# ICSSM_ICSSM_PR1_ICSSS_UART_UART_SLV_48028000h register map
Vendor: Texas Instruments
Peripheral module from a debugger description file (folder AM263X).
Registers are 32-bit, read-write, reset 0x0 unless marked. A register's access mark holds for its fields unless they carry their own. Offsets are as the file gives them; lines under a group give offsets from that group; [hi:lo] are bit positions; {n}, {i} and the like mark numbered series; 'fields as' and 'values as' point back to an identical list; <NAME> marks a mode.

## ICSSM_PR1_ICSSS_UART_UART_SLV
0x00 ICSSM_PR1_ICSSS_UART_UART_SLV_RBR ro — Receiver Buffer Register (read only)The UART receiver section consists of a receiver shift register (RSR) and a receiver buffer register (RBR). When the UART is in the FIFO mode, RBR is a 16-byte FIFO. Timing is supplied by the 16x receiver clock or 13x receiver clock by programming OSM_SEL bit field of MDR register. Receiver section control is a function of the line control register (LCR).RSR receives serial data from the UARTn_RXD pin. Then RSR concatenates the data and moves it into RBR (or the receiver FIFO). In the non-FIFO mode, when a character is placed in RBR and the receiver data-ready interrupt is enabled (DR = 1 in IER), an interrupt is generated. This interrupt is cleared when the character is read from RBR. In the FIFO mode, the interrupt is generated when the FIFO is filled to the trigger level selected in the FIFO control register (FCR), and it is cleared when the FIFO contents drop below the trigger level.
  [7:0] DATA — Received Data
0x00 ICSSM_PR1_ICSSS_UART_UART_SLV_THR wo — The transmitter holding register (THR) (write only)The UART transmitter section consists of a transmitter hold register (THR) and a transmitter shift register (TSR). When the UART is in the FIFO mode, THR is a 16-byte FIFO. Transmitter section control is a function of the line control register (LCR).THR receives data from the internal data bus and when TSR is idle, the UART moves the data from THR to TSR. The UART serializes the data in TSR and transmits the data on the TX pin. In the non-FIFO mode, if THR is empty and the THR empty (THRE) interrupt is enabled (ETBEI = 1 in IER), an interrupt is generated. This interrupt is cleared when a character is loaded into THR or the interrupt identification register (IIR) is read. In the FIFO mode, the interrupt is generated when the transmitter FIFO is empty, and it is cleared when at least one byte is loaded into the FIFO or IIR is read.
  [7:0] DATA — Data to transmit
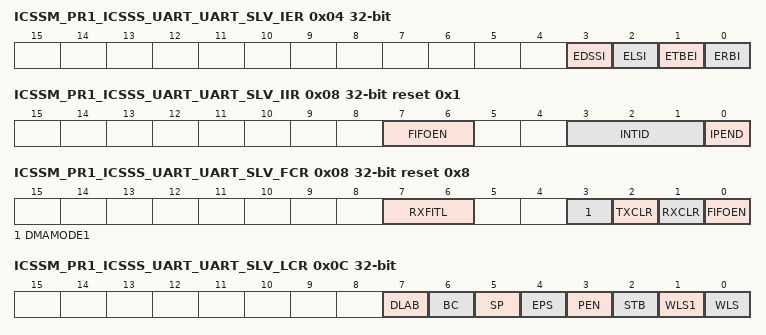
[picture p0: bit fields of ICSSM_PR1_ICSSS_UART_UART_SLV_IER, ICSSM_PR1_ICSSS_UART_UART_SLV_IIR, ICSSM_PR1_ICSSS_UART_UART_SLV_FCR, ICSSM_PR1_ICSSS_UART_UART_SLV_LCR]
0x04 ICSSM_PR1_ICSSS_UART_UART_SLV_IER — The interrupt enable register (IER) is used to individually enable or disable each type of interrupt request that can be generated by the UART. Each interrupt request that is enabled in IER is forwarded to the CPU.
  [3] EDSSI — Enable for Modem Status Interrupt
  [2] ELSI — Enable for Receiver Line Status Interrupt 0h Receiver line status interrupt is disabled.1h Received line status is enabled
  [1] ETBEI — Enable for Transmitter Holding Register Empty Interrupt 0h Transmitter holding register empty interrupt is disabled.1h Transmitter holding register empty interrupt is enabled.
  [0] ERBI — Enable for Receiver Data Available Interrupt 0h Receiver data available interrupt and character timeout indication interrupt is disabled.1h Receiver data available interrupt and character timeout indication interrupt is enabled.
0x08 ICSSM_PR1_ICSSS_UART_UART_SLV_IIR ro reset 0x1 — The interrupt identification register (IIR) is a read-only register at the same address as the FIFO control register (FCR), which is a write-only register. When an interrupt is generated and enabled in the interrupt enable register (IER), IIR indicates that an interrupt is pending in the IPEND bit and encodes the type of interrupt in the INTID bits. Reading IIR clears any THR empty (THRE) interrupts that are pending.
  [7:6] FIFOEN — FIFOs enabled 0h Non-FIFO mode1h-2h Reserved3h FIFOs are enabled. FIFOEN bit in the FIFO control register (FCR) is set to 1.
  [3:1] INTID — Interrupt Type 0h Reserved1h Transmitter holding register empty (priority 3)2h Receiver data available (priority 2)3h Receiver line status (priority 1, highest)4h-5h Reserved6h Character timeout indication (priority 2)7h Reserved
  [0] IPEND — Interrupt pending.When any UART interrupt is generated and is enabled in IER, IPEND is forced to 0. IPEND remains 0 until all pending interrupts are cleared or until a hardware reset occurs. If no interrupts are enabled, IPEND is never forced to 0. 0h Interrupts pending1h No interrupts pending
0x08 ICSSM_PR1_ICSSS_UART_UART_SLV_FCR wo reset 0x8 — FIFO Control Register (write only)The FIFO control register (FCR) is a write-only register at the same address as the interrupt identification register (IIR), which is a read-only register.
  [7:6] RXFITL — Receiver FIFO trigger level.RXFIFTL sets the trigger level for the receiver FIFO.When the trigger level is reached, a receiver data-ready interrupt is generated (if the interrupt request is enabled).Once the FIFO drops below the trigger level, the interrupt is cleared. 0h 1 byte1h 4 bytes2h 8 bytes3h 14 bytes
  [3] DMAMODE1 — DMA MODE1 enable if FIFOs are enabled.Always write 1 to DMAMODE1.After a hardware reset, change DMAMODE1 from 0 to 1.DMAMODE1 = 1 is a requirement for proper communication between the UART and the EDMA controller. 0h DMA MODE 1 is disabled1h DMA MODE 1 is enabled
  [2] TXCLR — Transmitter FIFO clear. Write a 1 to TXCLR to clear the bit. 0h No effect1h Clears transmitter FIFO and resets the transmitter FIFO counter. The shift register is not cleared.
  [1] RXCLR — Receiver FIFO clear. Write a 1 to RXCLR to clear the bit. 0h No effect1h Clears receiver FIFO and resets the receiver FIFO counter. The shift register is not cleared.
  [0] FIFOEN — Transmitter and receiver FIFOs mode enable. FIFOEN must be set before other FCR bits are written to or the FCR bits are not programmed. Clearing this bit clears the FIFO counters. 0h Non-FIFO mode. The transmitter and receiver FIFOs are disabled, and the FIFO pointers are cleared.1h FIFO mode. The transmitter and receiver FIFOs are enabled.
0x0C ICSSM_PR1_ICSSS_UART_UART_SLV_LCR — Line Control Register (LCR)The system programmer controls the format of the asynchronous data communication exchange by using LCR. In addition, the programmer can retrieve, inspect, and modify the content of LCR; this eliminates the need for separate storage of the line characteristics in system memory.
  [7] DLAB — Divisor latch access bit. The divisor latch registers (DLL and DLH) can be accessed at dedicated addresses or at addresses shared by RBR, THR, and IER. Using the shared addresses requires toggling DLAB to change which registers are selected. If you use the dedicated addresses, you can keep DLAB = 0. 0 Allows access to the receiver buffer register (RBR), the transmitter holding register (THR), and the interrupt enable register (IER) selected. At the address shared by RBR, THR, and DLL, the CPU can read from RBR and write to THR. At the address shared by IER and DLH, the CPU can read from and write to IER.1 Allows access to the divisor latches of the baud generator during a read or write operation (DLL and DLH). At the address shared by RBR, THR, and DLL, the CPU can read from and write to DLL. At the address shared by IER and DLH, the CPU can read from and write to DLH.
  [6] BC — Break Control 0 Break condition is disabled1 Break condition is transmitted to the receiving UART. A break condition is a condition where the UARTn_TXD signal is forced to the spacing (cleared) state.
  [5] SP — Stick parity. The SP bit works in conjunction with the EPS and PEN bits. 0 Stick parity is disabled1 Stick parity is enabled -When odd parity is selected (EPS = 0), the PARITY bit is transmitted and checked as set. -When even parity is selected (EPS = 1), the PARITY bit is transmitted and checked as cleared.
  [4] EPS — Even parity select. Selects the parity when parity is enabled (PEN = 1). The EPS bit works in conjunction with the SP and PEN bits. 0 Odd parity is selected (an odd number of logic 1s is transmitted or checked in the data and PARITY bits).1 Even parity is selected (an even number of logic 1s is transmitted or checked in the data and PARITY bits).
  [3] PEN — Parity enable. The PEN bit works in conjunction with the SP and EPS bits. 0 No PARITY bit is transmitted or checked.1 Parity bit is generated in transmitted data and is checked in received data between the last data word bit and the first STOP bit.
  [2] STB — Number of STOP bits generated. STB specifies 1, 1.5, or 2 STOP bits in each transmitted character. When STB = 1, the WLS bit determines the number of STOP bits. The receiver clocks only the first STOP bit, regardless of the number of STOP bits selected. 0 1 STOP bit is generated.1 WLS bit determines the number of STOP bits: -When WLS = 0, 1.5 STOP bits are generated. -When WLS = 1h, 2h, or 3h, 2 STOP bits are generated.
  [1] WLS1 — Word Length Select Bit 1
  [0] WLS — Word length select.Number of bits in each transmitted or received serial character. When STB = 1, the WLS bit determines the number of STOP bits. 0 5 bits1 6 bits2 7 bits3 8 bits
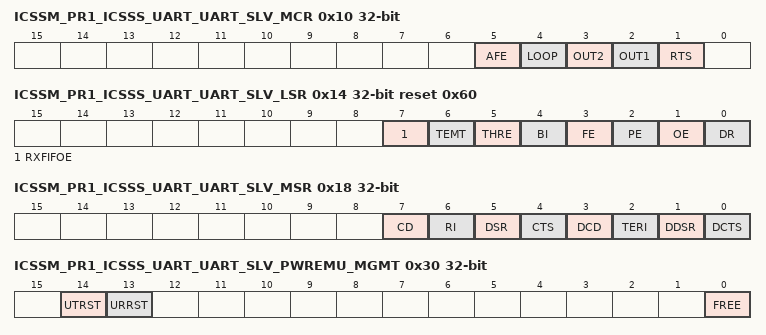
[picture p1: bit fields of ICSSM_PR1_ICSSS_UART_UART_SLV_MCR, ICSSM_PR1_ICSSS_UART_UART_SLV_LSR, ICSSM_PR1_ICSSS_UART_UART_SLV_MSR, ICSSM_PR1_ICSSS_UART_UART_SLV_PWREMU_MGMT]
0x10 ICSSM_PR1_ICSSS_UART_UART_SLV_MCR — Modem Control Register (MCR)The modem control register provides the ability to enable/disable the autoflow functions, and enable/disable the loopback function for diagnostic purposes.
  [5] AFE — Autoflow control enable.Autoflow control allows the UARTn_RTS and UARTn_CTS signals to provide handshaking between UARTs during data transfer. When AFE = 1, the RTS bit determines the autoflow control enabled. Note that all UARTs do not support this feature, see your device-specific data manual for supported features. If this feature is not available, this bit is reserved and should be cleared to 0. 0 Autoflow control is disabled.1 Autoflow control is enabled: -When RTS = 0, UARTnCTS is only enabled -When RTS = 1, UARTn_RTS and UARTn_CTS are enabled
  [4] LOOP — Loop back mode enable. LOOP is used for the diagnostic testing using the loop back feature. 0 Loop back mode is disabled.1 Loop back mode is enabled. When LOOP is set, the following occur: -The UARTn_TXD signal is set high. -The UARTn_RXD pin is disconnected -The output of the transmitter shift register (TSR) is lopped back in to the receiver shift register (RSR) input.
  [3] OUT2 — Out2 Bit
  [2] OUT1 — Out1 Bit
  [1] RTS — RTS control. When AFE = 1, the RTS bit determines the autoflow control enabled. Note that all UARTs do not support this feature, see your device-specific data manual for supported features. If this feature is not available, this bit is reserved and should be cleared to 0. 0 UARTn_RTS is disabled, UARTn_CTS is only enabled.1 UARTn_RTS and UARTn_CTS are enabled.
0x14 ICSSM_PR1_ICSSS_UART_UART_SLV_LSR ro reset 0x60 — Line Status Register (LSR)LSR provides information to the CPU concerning the status of data transfers. LSR is intended for read operations only; do not write to this register. Bits 1 through 4 record the error conditions that produce a receiver line status interrupt.
  [7] RXFIFOE — Receiver FIFO error.In non-FIFO mode:0 = There has been no error, or RXFIFOE was cleared because the CPU read the erroneous character from the receiver buffer register (RBR).1 = There is a parity error, framing error, or break indicator in the receiver buffer register (RBR).In FIFO mode:0 = There has been no error, or RXFIFOE was cleared because the CPU read the erroneous character from the receiver FIFO and there are no more errors in the receiver FIFO.1 = At least one parity error, framing error, or break indicator in the receiver FIFO.
  [6] TEMT — Transmitter empty (TEMT) indicator.In non-FIFO mode:0 = Either the transmitter holding register (THR) or the transmitter shift register (TSR) contains a data character.1 = Both the transmitter holding register (THR) and the transmitter shift register (TSR) are empty.In FIFO mode:0 = Either the transmitter FIFO or the transmitter shift register (TSR) contains a data character.1 = Both the transmitter FIFO and the transmitter shift register (TSR) are empty.
  [5] THRE — Transmitter holding register empty (THRE) indicator.If the THRE bit is set and the corresponding interrupt enable bit is set (ETBEI = 1 in IER), an interrupt request is generated.In non-FIFO mode:0 = Transmitter holding register (THR) is not empty. THR has been loaded by the CPU.1 = Transmitter holding register (THR) is empty (ready to accept a new character). The content of THR has been transferred to the transmitter shift register (TSR).In FIFO mode:0 = Transmitter FIFO is not empty. At least one character has been written to the transmitter FIFO. You can write to the transmitter FIFO if it is not full.1 = Transmitter FIFO is empty. The last character in the FIFO has been transferred to the transmitter shift register (TSR).
  [4] BI — Break indicator.The BI bit is set whenever the receive data input (UARTn_RXD) was held low for longer than a full-word transmission time. A full-word transmission time is defined as the total time to transmit the START, data, PARITY, and STOP bits. If the BI bit is set and the corresponding interrupt enable bit is set (ELSI = 1 in IER), an interrupt request is generated.In non-FIFO mode:0 = No break has been detected, or the BI bit was cleared because the CPU read the erroneous character from the receiver buffer register (RBR).1 = A break has been detected with the character in the receiver buffer register (RBR).In FIFO mode:0 = No break has been detected, or the BI bit was cleared because the CPU read the erroneous character from the receiver FIFO and the next character to be read from the FIFO has no break indicator.1 = A break has been detected with the character at the top of the receiver FIFO.
  [3] FE — Framing error (FE) indicator.A framing error occurs when the received character does not have a valid STOP bit. In response to a framing error, the UART sets the FE bit and waits until the signal on the RX pin goes high. Once the RX signal goes high, the receiver is ready to detect a new START bit and receive new data. If the FE bit is set and the corresponding interrupt enable bit is set (ELSI = 1 in IER), an interrupt request is generated.In non-FIFO mode:0 = No framing error has been detected, or the FE bit was cleared because the CPU read the erroneous data from the receiver buffer register (RBR).1 = A framing error has been detected with the character in the receiver buffer register (RBR).In FIFO mode:0 = No framing error has been detected, or the FE bit was cleared because the CPU read the erroneous data from the receiver FIFO and the next character to be read from the FIFO has no framing error.1 = A framing error has been detected with the character at the top of the receiver FIFO.
  [2] PE — Parity error (PE) indicator. A parity error occurs when the parity of the received character does not match the parity selected with the EPS bit in the line control register (LCR). If the PE bit is set and the corresponding interrupt enable bit is set (ELSI = 1 in IER), an interrupt request is generated.In non-FIFO mode:0 = No parity error has been detected, or the PE bit was cleared because the CPU read the erroneous data from the receiver buffer register (RBR).1 = A parity error has been detected with the character in the receiver buffer register (RBR).In FIFO mode:0 = No parity error has been detected, or the PE bit was cleared because the CPU read the erroneous data from the receiver FIFO and the next character to be read from the FIFO has no parity error.1 = A parity error has been detected with the character at the top of the receiver FIFO.
  [1] OE — Overrun error (OE) indicator. An overrun error in the non-FIFO mode is different from an overrun error in the FIFO mode. If the OE bit is set and the corresponding interrupt enable bit is set (ELSI = 1 in IER), an interrupt request is generated.In non-FIFO mode:0 = No overrun error has been detected, or the OE bit was cleared because the CPU read the content of the line status register (LSR).1 = Overrun error has been detected. Before the character in the receiver buffer register (RBR) could be read, it was overwritten by the next character arriving in RBR.In FIFO mode:0 = No overrun error has been detected, or the OE bit was cleared because the CPU read the content of the line status register (LSR).1 = Overrun error has been detected. If data continues to fill the FIFO beyond the trigger level, an overrun error occurs only after the FIFO is full and the next character has been completely received in the shift register. An overrun error is indicated to the CPU as soon as it happens. The new character overwrites the character in the shift register, but it is not transferred to the FIFO.
  [0] DR — Data-ready (DR) indicator for the receiver. If the DR bit is set and the corresponding interrupt enable bit is set (ERBI = 1 in IER), an interrupt request is generated.In non-FIFO mode:0 = Data is not ready, or the DR bit was cleared because the character was read from the receiver buffer register (RBR).1 = Data is ready. A complete incoming character has been received and transferred into the receiver buffer register (RBR).In FIFO mode:0 = Data is not ready, or the DR bit was cleared because all of the characters in the receiver FIFO have been read.1 = Data is ready. There is at least one unread character in the receiver FIFO. If the FIFO is empty, the DR bit is set as soon as a complete incoming character has been received and transferred into the FIFO. The DR bit remains set until the FIFO is empty again.
0x18 ICSSM_PR1_ICSSS_UART_UART_SLV_MSR ro — Modem Status Register (MSR)MSR provides information to the CPU concerning the status of modem control signals. MSR is intended for read operations only; do not write to this register.
  [7] CD — Complement of the Carrier Detect input. When the UART is in the diagnostic test mode (loopback mode MCR[4] = 1), this bit is equal to the MCR bit 3 (OUT2).
  [6] RI — Complement of the Ring Indicator input. When the UART is in the diagnostic test mode (loopback mode MCR[4] = 1), this bit is equal to the MCR bit 2 (OUT1).
  [5] DSR — Complement of the Data Set Ready input. When the UART is in the diagnostic test mode (loopback mode MCR[4] = 1), this bit is equal to the MCR bit 0 (DTR).
  [4] CTS — Complement of the Clear To Send input. When the UART is in the diagnostic test mode (loopback mode MCR[4] = 1), this bit is equal to the MCR bit 1 (RTS).
  [3] DCD — Change in DCD indicator bit. DCD indicates that the DCD input has changed state since the last time it was read by the CPU. When DCD is set and the modem status interrupt is enabled, a modem status interrupt is generated.
  [2] TERI — Trailing edge of RI (TERI) indicator bit. TERI indicates that the RI input has changed from a low to a high. When TERI is set and the modem status interrupt is enabled, a modem status interrupt is generated.
  [1] DDSR — Change in DSR indicator bit. DDSR indicates that the DSR input has changed state since the last time it was read by the CPU. When DDSR is set and the modem status interrupt is enabled, a modem status interrupt is generated.
  [0] DCTS — Change in CTS indicator bit. DCTS indicates that the CTS input has changed state since the last time it was read by the CPU. When DCTS is set (autoflow control is not enabled and the modem status interrupt is enabled), a modem status interrupt is generated. When autoflow control is enabled, no interrupt is generated.
0x1C ICSSM_PR1_ICSSS_UART_UART_SLV_SCR — Scratch Pad Register (SCR)SCR is intended for programmer's use as a scratch pad. It temporarily holds the programmer's data without affecting UART operation.
  [7:0] DATA — Scratch Register BitsThese bits are intended for the programmer's use as a scratch pad in the sense that it temporarily holds the programmer's data without affecting any other UART operation.
0x20 ICSSM_PR1_ICSSS_UART_UART_SLV_DLL — Divisor LSB Latch.
  [7:0] DLL — The 8 least-significant bits (LSBs) of the 16-bit divisor for generation of the baud clock in the baud rate generator.
0x24 ICSSM_PR1_ICSSS_UART_UART_SLV_DLH — Divisor MSB Latch.
  [7:0] DLH — The 8 most-significant bits (MSBs) of the 16-bit divisor for generation of the baud clock in the baud rate generator.
0x28 ICSSM_PR1_ICSSS_UART_UART_SLV_REVID1 ro reset 0x11020002 — Revision Identification Register 1
  [31:0] REVID1 — Peripheral Identification Number
0x2C ICSSM_PR1_ICSSS_UART_UART_SLV_REVID2 ro — Revision Identification Register 2
  [7:0] REVID2 — Peripheral Identification Number
0x30 ICSSM_PR1_ICSSS_UART_UART_SLV_PWREMU_MGMT — UART PowerManagement and Emulation Register.
  [14] UTRST — UART transmitter reset. Resets and enables the transmitter. 0 Transmitter is disabled and in reset state.1 Transmitter is enabled.
  [13] URRST — UART receiver reset. Resets and enables the receiver. 0 Receiver is disabled and in reset state.1 Receiver is enabled.
  [0] FREE — Free-running enable mode bit. This bit determines the emulation mode functionality of the UART. When halted, the UART can handle register read/write requests, but does not generate any transmission/reception, interrupts or events. 0 If a transmission is not in progress, the UART halts immediately. If a transmission is in progress, the UART halts after completion of the one-word transmission.1 Free-running mode is enabled; UART continues to run normally.
0x34 ICSSM_PR1_ICSSS_UART_UART_SLV_MDR — UART Mode Definition Register.
  [0] OSM_SEL — Over-Sampling Mode Select 0 16x over-sampling1 13x over-sampling
